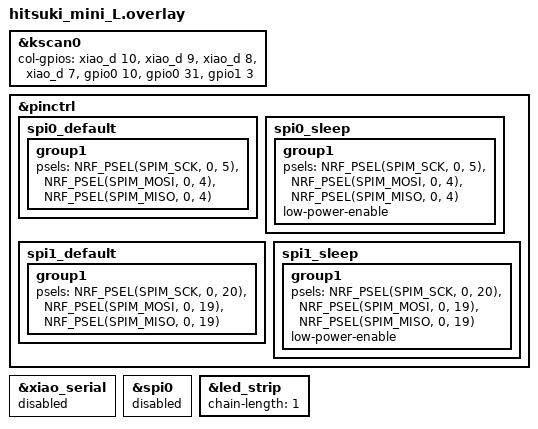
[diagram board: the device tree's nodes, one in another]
#include "hitsuki_mini.dtsi"

&kscan0 {
    col-gpios
        = <&xiao_d 10 GPIO_ACTIVE_HIGH>
        , <&xiao_d 9 GPIO_ACTIVE_HIGH>
        , <&xiao_d 8 GPIO_ACTIVE_HIGH>
        , <&xiao_d 7 GPIO_ACTIVE_HIGH>
        , <&gpio0 10 GPIO_ACTIVE_HIGH>
        , <&gpio0 31 GPIO_ACTIVE_HIGH>
        , <&gpio1 3 GPIO_ACTIVE_HIGH>
        ;
};

&pinctrl {
    spi0_default: spi0_default {
        group1 {
            psels = <NRF_PSEL(SPIM_SCK, 0, 5)>,
                <NRF_PSEL(SPIM_MOSI, 0, 4)>,
                <NRF_PSEL(SPIM_MISO, 0, 4)>;
        };
    };

    spi0_sleep: spi0_sleep {
        group1 {
            psels = <NRF_PSEL(SPIM_SCK, 0, 5)>,
                <NRF_PSEL(SPIM_MOSI, 0, 4)>,
                <NRF_PSEL(SPIM_MISO, 0, 4)>;
            low-power-enable;
        };
    };

    spi1_default: spi1_default {
        group1 {
            psels = <NRF_PSEL(SPIM_SCK, 0, 20)>,
                <NRF_PSEL(SPIM_MOSI, 0, 19)>,
                <NRF_PSEL(SPIM_MISO, 0, 19)>;
        };
    };

    spi1_sleep: spi1_sleep {
        group1 {
            psels = <NRF_PSEL(SPIM_SCK, 0, 20)>,
                <NRF_PSEL(SPIM_MOSI, 0, 19)>,
                <NRF_PSEL(SPIM_MISO, 0, 19)>;
            low-power-enable;
        };
    };
};

&xiao_serial {
    status = "disabled";
};

&spi0 {
    status = "disabled";
};

&led_strip {
    status = "okay";
    chain-length = <1>;
};
